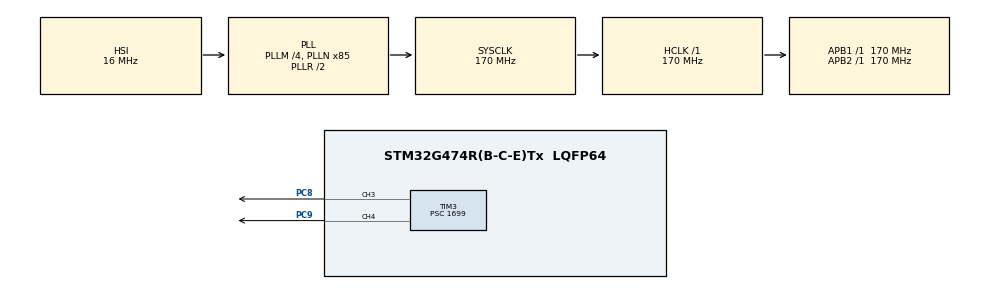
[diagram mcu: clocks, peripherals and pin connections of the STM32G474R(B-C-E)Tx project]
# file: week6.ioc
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Mcu.Family=STM32G4
Mcu.Name=STM32G474R(B-C-E)Tx
Mcu.Package=LQFP64
NVIC.PriorityGroup=NVIC_PRIORITYGROUP_4
PA13.GPIO_Label=T_SWDIO
PA13.Signal=SYS_JTMS-SWDIO
PA14.GPIO_Label=T_SWCLK
PA14.Signal=SYS_JTCK-SWCLK
PA2.GPIO_Label=LPUART1_TX [STLINKV3E_VCP_RX]
PA2.Signal=LPUART1_TX
PA3.GPIO_Label=LPUART1_RX [STLINKV3E_VCP_TX]
PA3.Signal=LPUART1_RX
PB3.GPIO_Label=T_SWO
PB3.Signal=SYS_JTDO-SWO
PC14-OSC32_IN.GPIO_Label=RCC_OSC32_IN
PC14-OSC32_IN.Signal=RCC_OSC32_IN
PC15-OSC32_OUT.GPIO_Label=RCC_OSC32_OUT
PC15-OSC32_OUT.Signal=RCC_OSC32_OUT
PC8.Signal=S_TIM3_CH3
PC9.Signal=S_TIM3_CH4
PF0-OSC_IN.GPIO_Label=RCC_OSC_IN
PF0-OSC_IN.Signal=RCC_OSC_IN
PF1-OSC_OUT.GPIO_Label=RCC_OSC_OUT
PF1-OSC_OUT.Signal=RCC_OSC_OUT
ProjectManager.HeapSize=0x200
ProjectManager.StackSize=0x400
ProjectManager.TargetToolchain=STM32CubeIDE
RCC.ADC12Freq_Value=170000000
RCC.ADC345Freq_Value=170000000
RCC.AHBFreq_Value=170000000
RCC.APB1Freq_Value=170000000
RCC.APB1TimFreq_Value=170000000
RCC.APB2Freq_Value=170000000
RCC.APB2TimFreq_Value=170000000
RCC.CortexFreq_Value=170000000
RCC.EXTERNAL_CLOCK_VALUE=12288000
RCC.HCLKFreq_Value=170000000
RCC.HSE_VALUE=24000000
RCC.HSI48_VALUE=48000000
RCC.HSI_VALUE=16000000
RCC.LSE_VALUE=32768
RCC.PLLM=RCC_PLLM_DIV4
RCC.PLLN=85
RCC.RTCClockSelection=RCC_RTCCLKSOURCE_LSE
RCC.SYSCLKFreq_VALUE=170000000
RCC.SYSCLKSource=RCC_SYSCLKSOURCE_PLLCLK
RCC.USBFreq_Value=170000000
RCC.VCOOutputFreq_Value=340000000
SH.S_TIM3_CH3.0=TIM3_CH3,PWM Generation3 CH3
SH.S_TIM3_CH4.0=TIM3_CH4,PWM Generation4 CH4
TIM3.Channel-PWM\ Generation3\ CH3=TIM_CHANNEL_3
TIM3.Channel-PWM\ Generation4\ CH4=TIM_CHANNEL_4
TIM3.PeriodNoDither=19999
TIM3.Prescaler=1699
TIM3.PulseNoDither_3=4000
TIM3.PulseNoDither_4=16000
VP_SYS_VS_DBSignals.Mode=DisableDeadBatterySignals
VP_TIM3_VS_ClockSourceINT.Mode=Internal
board=NUCLEO-G474RE

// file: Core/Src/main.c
/* USER CODE BEGIN Header */
/**
  ******************************************************************************
  * @file           : main.c
  * @brief          : Main program body
  ******************************************************************************
  * @attention
  *
  * Copyright (c) 2026 STMicroelectronics.
  * All rights reserved.
  *
  * This software is licensed under terms that can be found in the LICENSE file
  * in the root directory of this software component.
  * If no LICENSE file comes with this software, it is provided AS-IS.
  *
  ******************************************************************************
  */
/* USER CODE END Header */
#include "main.h"

TIM_HandleTypeDef htim3;

void SystemClock_Config(void);
static void MX_GPIO_Init(void);
static void MX_TIM3_Init(void);

/* USER CODE BEGIN 0 */
/* USER CODE BEGIN 0 */

#define BREATH_MAX       1000
#define BREATH_STEP      5
#define BREATH_INTERVAL  5

uint32_t last_update_time = 0;
int32_t brightness = 0;
int32_t direction = 1;

/* USER CODE END 0 */
/* USER CODE END 0 */

int main(void)
{

  /* MCU Configuration--------------------------------------------------------*/

  /* Reset of all peripherals, Initializes the Flash interface and the Systick. */
  HAL_Init();

  /* Configure the system clock */
  SystemClock_Config();

  /* Initialize all configured peripherals */
  MX_GPIO_Init();
  MX_TIM3_Init();
  /* USER CODE BEGIN 2 */
  /* USER CODE BEGIN 2 */

  HAL_TIM_PWM_Start(&htim3, TIM_CHANNEL_3);

  /* USER CODE END 2 */
  /* USER CODE END 2 */

  /* Infinite loop */
  /* USER CODE BEGIN WHILE */
  while (1)
  {
      uint32_t current_time = HAL_GetTick();

      // 每隔 5 ms 更新一次亮度
      if (current_time - last_update_time >= BREATH_INTERVAL)
      {
          last_update_time = current_time;

          // 調整亮度
          brightness += direction * BREATH_STEP;

          // 到達最亮，開始變暗
          if (brightness >= BREATH_MAX)
          {
              brightness = BREATH_MAX;
              direction = -1;
          }

          // 到達最暗，開始變亮
          else if (brightness <= 0)
          {
              brightness = 0;
              direction = 1;
          }

          // 依照目前亮度計算 PWM 比較值
          uint32_t arr = __HAL_TIM_GET_AUTORELOAD(&htim3);

          uint32_t compare_value =
              ((arr + 1U) * (uint32_t)brightness) / BREATH_MAX;

          // 更新 TIM3 CH3 的 PWM 亮度
          __HAL_TIM_SET_COMPARE(
              &htim3,
              TIM_CHANNEL_3,
              compare_value
          );
      }
  }
}

void SystemClock_Config(void)
{
  RCC_OscInitTypeDef RCC_OscInitStruct = {0};
  RCC_ClkInitTypeDef RCC_ClkInitStruct = {0};

  /** Configure the main internal regulator output voltage
  */
  HAL_PWREx_ControlVoltageScaling(PWR_REGULATOR_VOLTAGE_SCALE1_BOOST);

  /** Initializes the RCC Oscillators according to the specified parameters
  * in the RCC_OscInitTypeDef structure.
  */
  RCC_OscInitStruct.OscillatorType = RCC_OSCILLATORTYPE_HSI;
  RCC_OscInitStruct.HSIState = RCC_HSI_ON;
  RCC_OscInitStruct.HSICalibrationValue = RCC_HSICALIBRATION_DEFAULT;
  RCC_OscInitStruct.PLL.PLLState = RCC_PLL_ON;
  RCC_OscInitStruct.PLL.PLLSource = RCC_PLLSOURCE_HSI;
  RCC_OscInitStruct.PLL.PLLM = RCC_PLLM_DIV4;
  RCC_OscInitStruct.PLL.PLLN = 85;
  RCC_OscInitStruct.PLL.PLLP = RCC_PLLP_DIV2;
  RCC_OscInitStruct.PLL.PLLQ = RCC_PLLQ_DIV2;
  RCC_OscInitStruct.PLL.PLLR = RCC_PLLR_DIV2;
  if (HAL_RCC_OscConfig(&RCC_OscInitStruct) != HAL_OK)
  {
    Error_Handler();
  }

  /** Initializes the CPU, AHB and APB buses clocks
  */
  RCC_ClkInitStruct.ClockType = RCC_CLOCKTYPE_HCLK|RCC_CLOCKTYPE_SYSCLK
                              |RCC_CLOCKTYPE_PCLK1|RCC_CLOCKTYPE_PCLK2;
  RCC_ClkInitStruct.SYSCLKSource = RCC_SYSCLKSOURCE_PLLCLK;
  RCC_ClkInitStruct.AHBCLKDivider = RCC_SYSCLK_DIV1;
  RCC_ClkInitStruct.APB1CLKDivider = RCC_HCLK_DIV1;
  RCC_ClkInitStruct.APB2CLKDivider = RCC_HCLK_DIV1;

  if (HAL_RCC_ClockConfig(&RCC_ClkInitStruct, FLASH_LATENCY_4) != HAL_OK)
  {
    Error_Handler();
  }
}

static void MX_TIM3_Init(void)
{

  TIM_ClockConfigTypeDef sClockSourceConfig = {0};
  TIM_MasterConfigTypeDef sMasterConfig = {0};
  TIM_OC_InitTypeDef sConfigOC = {0};

  htim3.Instance = TIM3;
  htim3.Init.Prescaler = 16;
  htim3.Init.CounterMode = TIM_COUNTERMODE_UP;
  htim3.Init.Period = 999;
  htim3.Init.ClockDivision = TIM_CLOCKDIVISION_DIV1;
  htim3.Init.AutoReloadPreload = TIM_AUTORELOAD_PRELOAD_DISABLE;
  if (HAL_TIM_Base_Init(&htim3) != HAL_OK)
  {
    Error_Handler();
  }
  sClockSourceConfig.ClockSource = TIM_CLOCKSOURCE_INTERNAL;
  if (HAL_TIM_ConfigClockSource(&htim3, &sClockSourceConfig) != HAL_OK)
  {
    Error_Handler();
  }
  if (HAL_TIM_PWM_Init(&htim3) != HAL_OK)
  {
    Error_Handler();
  }
  sMasterConfig.MasterOutputTrigger = TIM_TRGO_RESET;
  sMasterConfig.MasterSlaveMode = TIM_MASTERSLAVEMODE_DISABLE;
  if (HAL_TIMEx_MasterConfigSynchronization(&htim3, &sMasterConfig) != HAL_OK)
  {
    Error_Handler();
  }
  sConfigOC.OCMode = TIM_OCMODE_PWM1;
  sConfigOC.Pulse = 4000;
  sConfigOC.OCPolarity = TIM_OCPOLARITY_HIGH;
  sConfigOC.OCFastMode = TIM_OCFAST_DISABLE;
  if (HAL_TIM_PWM_ConfigChannel(&htim3, &sConfigOC, TIM_CHANNEL_3) != HAL_OK)
  {
    Error_Handler();
  }
  sConfigOC.Pulse = 16000;
  if (HAL_TIM_PWM_ConfigChannel(&htim3, &sConfigOC, TIM_CHANNEL_4) != HAL_OK)
  {
    Error_Handler();
  }
  HAL_TIM_MspPostInit(&htim3);

}

static void MX_GPIO_Init(void)
{
  GPIO_InitTypeDef GPIO_InitStruct = {0};

  /* GPIO Ports Clock Enable */
  __HAL_RCC_GPIOC_CLK_ENABLE();
  __HAL_RCC_GPIOF_CLK_ENABLE();
  __HAL_RCC_GPIOA_CLK_ENABLE();
  __HAL_RCC_GPIOB_CLK_ENABLE();

  /*Configure GPIO pins : LPUART1_TX_Pin LPUART1_RX_Pin */
  GPIO_InitStruct.Pin = LPUART1_TX_Pin|LPUART1_RX_Pin;
  GPIO_InitStruct.Mode = GPIO_MODE_AF_PP;
  GPIO_InitStruct.Pull = GPIO_NOPULL;
  GPIO_InitStruct.Speed = GPIO_SPEED_FREQ_LOW;
  GPIO_InitStruct.Alternate = GPIO_AF12_LPUART1;
  HAL_GPIO_Init(GPIOA, &GPIO_InitStruct);

}

void Error_Handler(void)
{
  __disable_irq();
  while (1)
  {
  }
}
